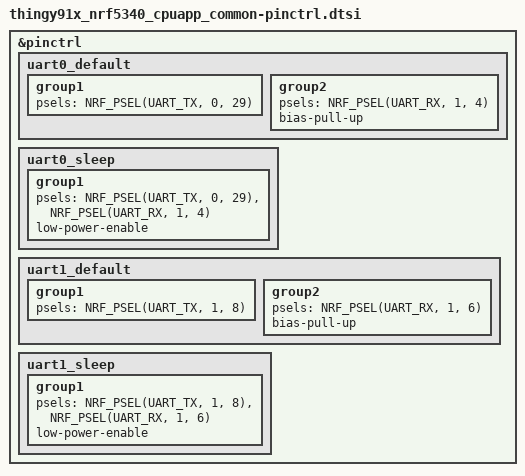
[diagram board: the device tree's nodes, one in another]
/*
 * Copyright (c) 2024 Nordic Semiconductor
 * SPDX-License-Identifier: LicenseRef-Nordic-5-Clause
 */

&pinctrl {
	uart0_default: uart0_default {
		group1 {
			psels = <NRF_PSEL(UART_TX, 0, 29)>;
		};
		group2 {
			psels = <NRF_PSEL(UART_RX, 1, 4)>;
			bias-pull-up;
		};
	};

	uart0_sleep: uart0_sleep {
		group1 {
			psels = <NRF_PSEL(UART_TX, 0, 29)>,
				<NRF_PSEL(UART_RX, 1, 4)>;
			low-power-enable;
		};
	};

	uart1_default: uart1_default {
		group1 {
			psels = <NRF_PSEL(UART_TX, 1, 8)>;
		};
		group2 {
			psels = <NRF_PSEL(UART_RX, 1, 6)>;
			bias-pull-up;
		};
	};

	uart1_sleep: uart1_sleep {
		group1 {
			psels = <NRF_PSEL(UART_TX, 1, 8)>,
				<NRF_PSEL(UART_RX, 1, 6)>;
			low-power-enable;
		};
	};
};
